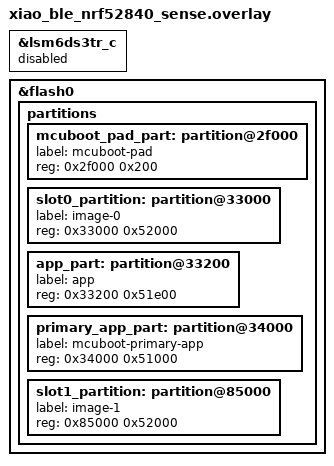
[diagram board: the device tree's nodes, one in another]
/*
 * MCUboot DTS overlay for XIAO nRF52840 Sense
 *
 * Same partition ordering as app overlay so that slot0/slot1 DTS IDs
 * match PM_MCUBOOT_PRIMARY_ID=3 and PM_MCUBOOT_SECONDARY_ID=6.
 */

/* Disable peripherals not needed in MCUboot */
&lsm6ds3tr_c {
    status = "disabled";
};

&flash0 {
    partitions {
        /* ID 2 */
        mcuboot_pad_part: partition@2f000 {
            label = "mcuboot-pad";
            reg = <0x2f000 0x200>;
        };

        /* ID 3 = PM_MCUBOOT_PRIMARY_ID → slot0_partition for MCUboot cmake */
        slot0_partition: partition@33000 {
            label = "image-0";
            reg = <0x33000 0x52000>;
        };

        /* ID 4 */
        app_part: partition@33200 {
            label = "app";
            reg = <0x33200 0x51e00>;
        };

        /* ID 5 */
        primary_app_part: partition@34000 {
            label = "mcuboot-primary-app";
            reg = <0x34000 0x51000>;
        };

        /* ID 6 = PM_MCUBOOT_SECONDARY_ID → slot1_partition for MCUboot cmake */
        slot1_partition: partition@85000 {
            label = "image-1";
            reg = <0x85000 0x52000>;
        };
    };
};
